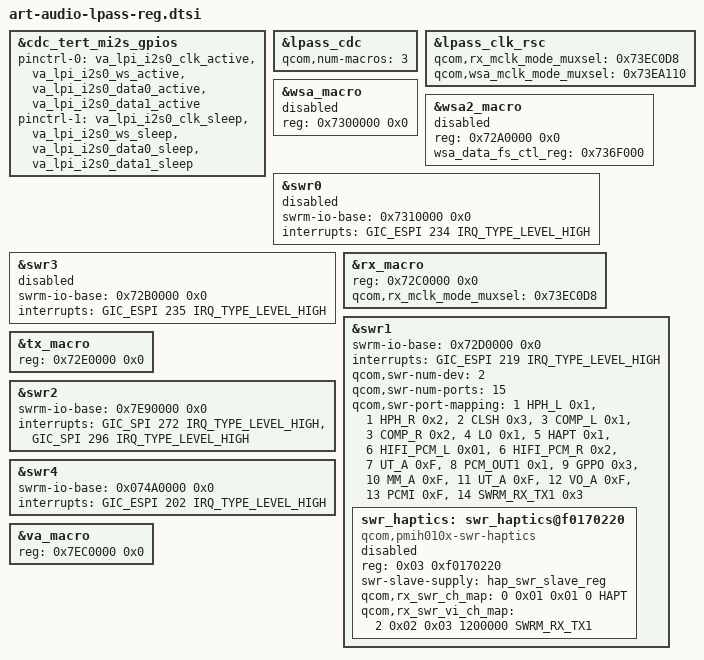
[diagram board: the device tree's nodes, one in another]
/*
 * Copyright (c) Qualcomm Technologies, Inc. and/or its subsidiaries.
 * SPDX-License-Identifier: BSD-3-Clause-Clear
*/

&cdc_tert_mi2s_gpios {
	pinctrl-0 = <&va_lpi_i2s0_clk_active &va_lpi_i2s0_ws_active
			&va_lpi_i2s0_data0_active &va_lpi_i2s0_data1_active>;
	pinctrl-1 = <&va_lpi_i2s0_clk_sleep &va_lpi_i2s0_ws_sleep
			&va_lpi_i2s0_data0_sleep &va_lpi_i2s0_data1_sleep>;
};

&lpass_cdc {
	qcom,num-macros = <3>;
};

&lpass_clk_rsc {
	qcom,rx_mclk_mode_muxsel = <0x73EC0D8>;
	qcom,wsa_mclk_mode_muxsel = <0x73EA110>;
};

&wsa_macro {
	status = "disabled";
	reg = <0x7300000 0x0>;
};

&wsa2_macro {
	status = "disabled";
	reg = <0x72A0000 0x0>;
	/*Check IPCAT for below details*/
	wsa_data_fs_ctl_reg = <0x736F000>;
};

/* WSA_SWR
 * vector# is within ESPI range (4096-5119) and use GIC_ESPI
 * vector# - 4096
 */
&swr0 {
	status = "disabled";
	swrm-io-base = <0x7310000 0x0>;
	interrupts = <GIC_ESPI 234 IRQ_TYPE_LEVEL_HIGH>;
};

/* WSA2_SWR */
&swr3 {
	status = "disabled";
	swrm-io-base = <0x72B0000 0x0>;
	interrupts = <GIC_ESPI 235 IRQ_TYPE_LEVEL_HIGH>;
};

&rx_macro  {
	reg = <0x72C0000 0x0>;
	/*Check IPCAT for address*/
	qcom,rx_mclk_mode_muxsel = <0x73EC0D8>;
};

/* RX_SWR */
&swr1 {
	swrm-io-base = <0x72D0000 0x0>;
	interrupts = <GIC_ESPI 219 IRQ_TYPE_LEVEL_HIGH>;
	qcom,swr-num-dev = <2>;
	qcom,swr-num-ports = <15>;
	qcom,swr-port-mapping = <1 HPH_L 0x1>, <1 HPH_R 0x2>,
				 <2 CLSH 0x3>, <3 COMP_L 0x1>,
				 <3 COMP_R 0x2>, <4 LO 0x1>, <5 HAPT 0x1>,
				 <6 HIFI_PCM_L 0x01>, <6 HIFI_PCM_R 0x2>,
				 <7 UT_A 0xF>, <8 PCM_OUT1 0x1>, <9 GPPO 0x3>,
				 <10 MM_A 0xF>, <11 UT_A 0xF>, <12 VO_A 0xF>,
				 <13 PCMI 0xF>, <14 SWRM_RX_TX1 0x3>;

	swr_haptics: swr_haptics@f0170220 {
		status = "disabled";
		compatible = "qcom,pmih010x-swr-haptics";
		reg = <0x03 0xf0170220>;
		swr-slave-supply = <&hap_swr_slave_reg>;
		qcom,rx_swr_ch_map = <0 0x01 0x01 0 HAPT>;
		qcom,rx_swr_vi_ch_map = <2 0x02 0x03 1200000 SWRM_RX_TX1>;
	};
};

&tx_macro  {
	reg = <0x72E0000 0x0>;
};

/* TX_SWR
 * vector# is within SPI range (32-992) and Use GIC_SPI
 * To get the interrupt vector# - 32
 */
&swr2 {
	swrm-io-base = <0x7E90000 0x0>;
	interrupts = <GIC_SPI 272 IRQ_TYPE_LEVEL_HIGH>,
		     <GIC_SPI 296 IRQ_TYPE_LEVEL_HIGH>;
};

/* BT_SWR */
&swr4 {
	swrm-io-base = <0x074A0000 0x0>;
	interrupts = <GIC_ESPI 202 IRQ_TYPE_LEVEL_HIGH>;
};

&va_macro {
	reg = <0x7EC0000 0x0>;
};
